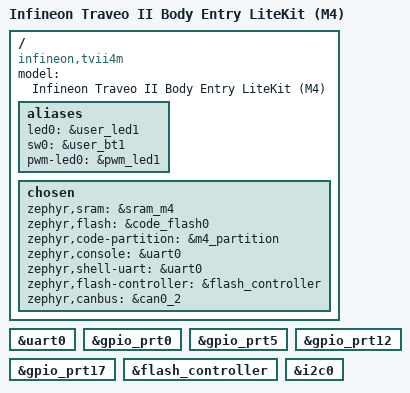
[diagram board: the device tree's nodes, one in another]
/*
 * Copyright (c) 2026 Linumiz
 * Copyright (c) 2026 Infineon Technologies AG
 * SPDX-License-Identifier: Apache-2.0
 */

/dts-v1/;

#include "kit_t2g_b_e_lite.dtsi"
#include <infineon/cat1a/cyt2bl/cyt2bl_m4.dtsi>

/ {
	model = "Infineon Traveo II Body Entry LiteKit (M4)";
	compatible = "infineon,tvii4m";

	aliases {
		led0 = &user_led1;
		sw0 = &user_bt1;
		pwm-led0 = &pwm_led1;
	};

	chosen {
		zephyr,sram = &sram_m4;
		zephyr,flash = &code_flash0;
		zephyr,code-partition = &m4_partition;
		zephyr,console = &uart0;
		zephyr,shell-uart = &uart0;
		zephyr,flash-controller = &flash_controller;
		zephyr,canbus = &can0_2;
	};
};

&uart0 {
	status = "okay";
};

&gpio_prt0 {
	status = "okay";
};

&gpio_prt5 {
	status = "okay";
};

&gpio_prt12 {
	status = "okay";
};

&gpio_prt17 {
	status = "okay";
};

&flash_controller {
	status = "okay";
};

&i2c0 {
	status = "okay";
};
